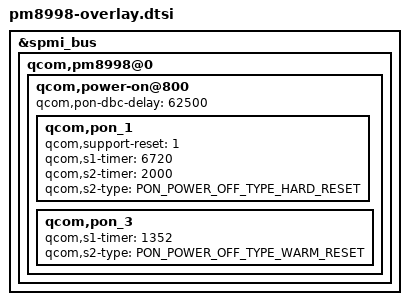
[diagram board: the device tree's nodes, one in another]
&spmi_bus {
    qcom,pm8998@0 {
        qcom,power-on@800 {
            qcom,pon-dbc-delay = <62500>;
            qcom,pon_1 {
                qcom,support-reset = <1>;
                qcom,s1-timer = <6720>;
                qcom,s2-timer = <2000>;
                qcom,s2-type = <PON_POWER_OFF_TYPE_HARD_RESET>;
            };
            qcom,pon_3 {
                qcom,s1-timer = <1352>;
                qcom,s2-type = <PON_POWER_OFF_TYPE_WARM_RESET>;
            };
        };
    };
};
